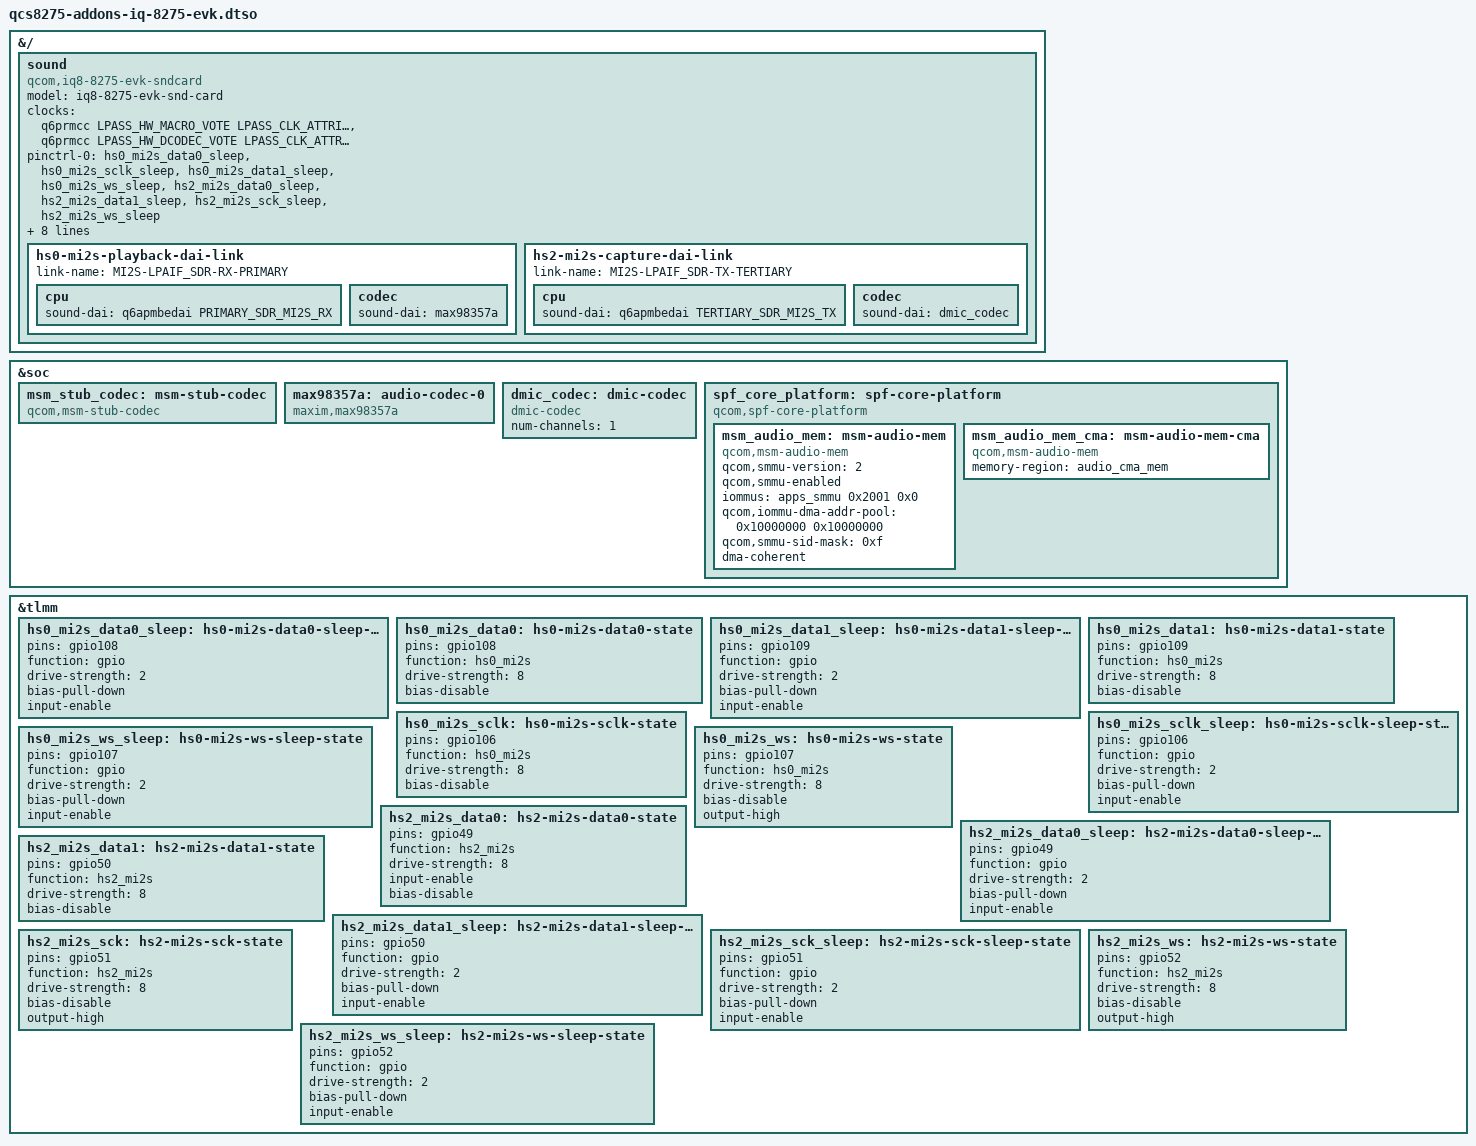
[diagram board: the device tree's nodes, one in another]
// SPDX-License-Identifier: BSD-3-Clause
/*
 * Copyright (c) 2025 Qualcomm Innovation Center, Inc. All rights reserved.
 */

/dts-v1/;
/plugin/;

#include "qcs8300-addons.dtsi"

&{/} {
	sound {
		compatible = "qcom,iq8-8275-evk-sndcard";
		model = "iq8-8275-evk-snd-card";

		clocks = <&q6prmcc LPASS_HW_MACRO_VOTE LPASS_CLK_ATTRIBUTE_COUPLE_NO>,
			    <&q6prmcc LPASS_HW_DCODEC_VOTE LPASS_CLK_ATTRIBUTE_COUPLE_NO>;
		clock-names = "macro", "dcodec";

		pinctrl-names = "default", "mi2s_aud_out_active", "mi2s_aud_out_sleep";
		pinctrl-0 = <&hs0_mi2s_data0_sleep>, <&hs0_mi2s_sclk_sleep>,
			    <&hs0_mi2s_data1_sleep>, <&hs0_mi2s_ws_sleep>,
			    <&hs2_mi2s_data0_sleep>, <&hs2_mi2s_data1_sleep>,
			    <&hs2_mi2s_sck_sleep>, <&hs2_mi2s_ws_sleep>;
		pinctrl-1 = <&hs0_mi2s_data0>, <&hs0_mi2s_sclk>,
			    <&hs0_mi2s_data1>, <&hs0_mi2s_ws>,
			    <&hs2_mi2s_data0>, <&hs2_mi2s_data1>,
			    <&hs2_mi2s_sck>, <&hs2_mi2s_ws>;
		pinctrl-2 = <&hs0_mi2s_data0_sleep>, <&hs0_mi2s_sclk_sleep>,
			    <&hs0_mi2s_data1_sleep>, <&hs0_mi2s_ws_sleep>,
			    <&hs2_mi2s_data0_sleep>, <&hs2_mi2s_data1_sleep>,
			    <&hs2_mi2s_sck_sleep>, <&hs2_mi2s_ws_sleep>;

		hs0-mi2s-playback-dai-link {
			link-name = "MI2S-LPAIF_SDR-RX-PRIMARY";

			cpu {
				sound-dai = <&q6apmbedai PRIMARY_SDR_MI2S_RX>;
			};

			codec {
				sound-dai = <&max98357a>;
			};
		};

		hs2-mi2s-capture-dai-link {
			link-name = "MI2S-LPAIF_SDR-TX-TERTIARY";

			cpu {
				sound-dai = <&q6apmbedai TERTIARY_SDR_MI2S_TX>;
			};

			codec {
				sound-dai = <&dmic_codec>;
			};
		};

	};
};

&soc {

	msm_stub_codec: msm-stub-codec {
		compatible = "qcom,msm-stub-codec";
		#sound-dai-cells = <1>;
	};

	max98357a: audio-codec-0 {
		compatible = "maxim,max98357a";
		#sound-dai-cells = <0>;
	};

	dmic_codec: dmic-codec {
		compatible = "dmic-codec";
		#sound-dai-cells = <0>;
		num-channels = <1>;
	};

	spf_core_platform: spf-core-platform {
		compatible = "qcom,spf-core-platform";

		msm_audio_mem: msm-audio-mem {
			compatible = "qcom,msm-audio-mem";
			qcom,smmu-version = <2>;
			qcom,smmu-enabled;
			iommus = <&apps_smmu 0x2001 0x0>;
			qcom,iommu-dma-addr-pool = <0x10000000 0x10000000>;
			qcom,smmu-sid-mask = /bits/ 64 <0xf>;
			dma-coherent;
		};

		msm_audio_mem_cma: msm-audio-mem-cma {
			compatible = "qcom,msm-audio-mem";
			memory-region = <&audio_cma_mem>;
		};
	};
};

&tlmm {
	hs0_mi2s_data0_sleep: hs0-mi2s-data0-sleep-state {
		pins = "gpio108";
		function = "gpio";
		drive-strength = <2>;
		bias-pull-down;
		input-enable;
	};

	hs0_mi2s_data0: hs0-mi2s-data0-state {
		pins = "gpio108";
		function = "hs0_mi2s";
		drive-strength = <8>;
		bias-disable;
	};

	hs0_mi2s_data1_sleep: hs0-mi2s-data1-sleep-state {
		pins = "gpio109";
		function = "gpio";
		drive-strength = <2>;
		bias-pull-down;
		input-enable;
	};

	hs0_mi2s_data1: hs0-mi2s-data1-state {
		pins = "gpio109";
		function = "hs0_mi2s";
		drive-strength = <8>;
		bias-disable;
	};

	hs0_mi2s_sclk_sleep: hs0-mi2s-sclk-sleep-state {
		pins = "gpio106";
		function = "gpio";
		drive-strength = <2>;
		bias-pull-down;
		input-enable;
	};

	hs0_mi2s_sclk: hs0-mi2s-sclk-state {
		pins = "gpio106";
		function = "hs0_mi2s";
		drive-strength = <8>;
		bias-disable;
	};

	hs0_mi2s_ws_sleep: hs0-mi2s-ws-sleep-state {
		pins = "gpio107";
		function = "gpio";
		drive-strength = <2>;
		bias-pull-down;
		input-enable;
	};

	hs0_mi2s_ws: hs0-mi2s-ws-state {
		pins = "gpio107";
		function = "hs0_mi2s";
		drive-strength = <8>;
		bias-disable;
		output-high;
	};

	hs2_mi2s_data0: hs2-mi2s-data0-state {
		pins = "gpio49";
		function = "hs2_mi2s";
		drive-strength = <8>;
		input-enable;
		bias-disable;
	};

	hs2_mi2s_data0_sleep: hs2-mi2s-data0-sleep-state {
		pins = "gpio49";
		function = "gpio";
		drive-strength = <2>;
		bias-pull-down;
		input-enable;
	};

	hs2_mi2s_data1: hs2-mi2s-data1-state {
		pins = "gpio50";
		function = "hs2_mi2s";
		drive-strength = <8>;
		bias-disable;
	};

	hs2_mi2s_data1_sleep: hs2-mi2s-data1-sleep-state {
		pins = "gpio50";
		function = "gpio";
		drive-strength = <2>;
		bias-pull-down;
		input-enable;
	};

	hs2_mi2s_sck: hs2-mi2s-sck-state {
		pins = "gpio51";
		function = "hs2_mi2s";
		drive-strength = <8>;
		bias-disable;
		output-high;
	};

	hs2_mi2s_sck_sleep: hs2-mi2s-sck-sleep-state {
		pins = "gpio51";
		function = "gpio";
		drive-strength = <2>;
		bias-pull-down;
		input-enable;
	};

	hs2_mi2s_ws: hs2-mi2s-ws-state {
		pins = "gpio52";
		function = "hs2_mi2s";
		drive-strength = <8>;
		bias-disable;
		output-high;
	};

	hs2_mi2s_ws_sleep: hs2-mi2s-ws-sleep-state {
		pins = "gpio52";
		function = "gpio";
		drive-strength = <2>;
		bias-pull-down;
		input-enable;
	};

};

